AUTOSAR XML (schema 00050)
package /FCADT/ComponentTypes
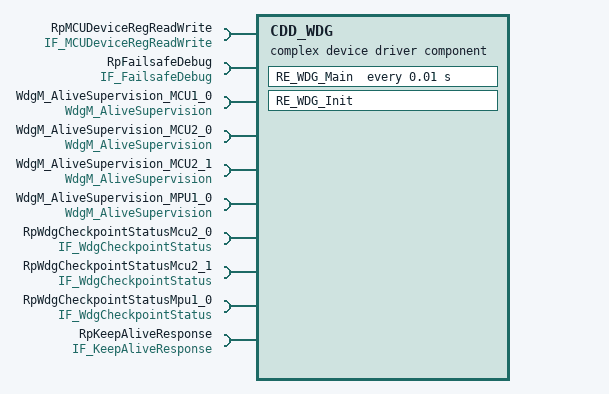
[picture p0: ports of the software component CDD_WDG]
  complex device driver sw component type CDD_WDG
    10 x require port:
      RpMCUDeviceRegReadWrite: required-com-specs=[MCUReadDeviceReg, MCUReadDeviceRegData, MCUWriteDeviceReg], required-interface=IF_MCUDeviceRegReadWrite
      RpFailsafeDebug: nonqueued-receiver-com-spec{data-element=Debugflag, filter=data-filter-type=ALWAYS, init-value=0}, required-interface=IF_FailsafeDebug
      WdgM_AliveSupervision_MCU1_0: client-com-spec=CheckpointReached, required-interface=WdgM_AliveSupervision
      WdgM_AliveSupervision_MCU2_0: client-com-spec=CheckpointReached, required-interface=WdgM_AliveSupervision
      WdgM_AliveSupervision_MCU2_1: client-com-spec=CheckpointReached, required-interface=WdgM_AliveSupervision
      WdgM_AliveSupervision_MPU1_0: client-com-spec=CheckpointReached, required-interface=WdgM_AliveSupervision
      RpWdgCheckpointStatusMcu2_0: nonqueued-receiver-com-spec{data-element=WdgCheckpointStatus_t, filter=data-filter-type=ALWAYS}, required-interface=IF_WdgCheckpointStatus
      RpWdgCheckpointStatusMcu2_1: nonqueued-receiver-com-spec{data-element=WdgCheckpointStatus_t, filter=data-filter-type=ALWAYS}, required-interface=IF_WdgCheckpointStatus
      RpWdgCheckpointStatusMpu1_0: nonqueued-receiver-com-spec{data-element=WdgCheckpointStatus_t, filter=data-filter-type=ALWAYS}, required-interface=IF_WdgCheckpointStatus
      RpKeepAliveResponse: nonqueued-receiver-com-spec{data-element=KeepAliveResponse_t, filter=data-filter-type=ALWAYS, init-value=fields=[FrameID_u32:0, ResponseCode_u8:0]}, required-interface=IF_KeepAliveResponse
    behavior CDD_WDG_InternalBehavior
      init event CDD_WDG_InitEvent: start-on-event=RE_WDG_Init
      timing event TMT_RE_WDG_Main: start-on-event=RE_WDG_Main, period=0.01
      runnable RE_WDG_Init
      runnable RE_WDG_Main
        data-receive-point-by-arguments:
          5 x access:
            REC_PpFailsafeDebug_Debugflag: accessed-variable=RpFailsafeDebug.Debugflag
            REC_RpWdgCheckpointStatus_WdgCheckpointStatus_t: accessed-variable=RpWdgCheckpointStatusMcu2_0.WdgCheckpointStatus_t
            REC_RpWdgCheckpointStatusMcu2_1_WdgCheckpointStatus_t: accessed-variable=RpWdgCheckpointStatusMcu2_1.WdgCheckpointStatus_t
            REC_RpWdgCheckpointStatusMpu1_0_WdgCheckpointStatus_t: accessed-variable=RpWdgCheckpointStatusMpu1_0.WdgCheckpointStatus_t
            REC_RpKeepAliveResponse_KeepAliveResponse_t: accessed-variable=RpKeepAliveResponse.KeepAliveResponse_t
        7 x sync call:
          SC_RpMCUDeviceRegReadWrite_MCUReadDeviceReg: operation=RpMCUDeviceRegReadWrite.MCUReadDeviceReg
          SC_RpMCUDeviceRegReadWrite_MCUReadDeviceRegData: operation=RpMCUDeviceRegReadWrite.MCUReadDeviceRegData
          SC_RpMCUDeviceRegReadWrite_MCUWriteDeviceReg: operation=RpMCUDeviceRegReadWrite.MCUWriteDeviceReg
          SC_WdgM_AliveSupervision_MCU1_0_CheckpointReached: operation=WdgM_AliveSupervision_MCU1_0.CheckpointReached
          SC_WdgM_AliveSupervision_MCU2_0_CheckpointReached: operation=WdgM_AliveSupervision_MCU2_0.CheckpointReached
          SC_WdgM_AliveSupervision_MCU2_1_CheckpointReached: operation=WdgM_AliveSupervision_MCU2_1.CheckpointReached
          SC_WdgM_AliveSupervision_MPU1_0_CheckpointReached: operation=WdgM_AliveSupervision_MPU1_0.CheckpointReached
  swc implementation CDD_WDG_Implementation: behavior=CDD_WDG_InternalBehavior
